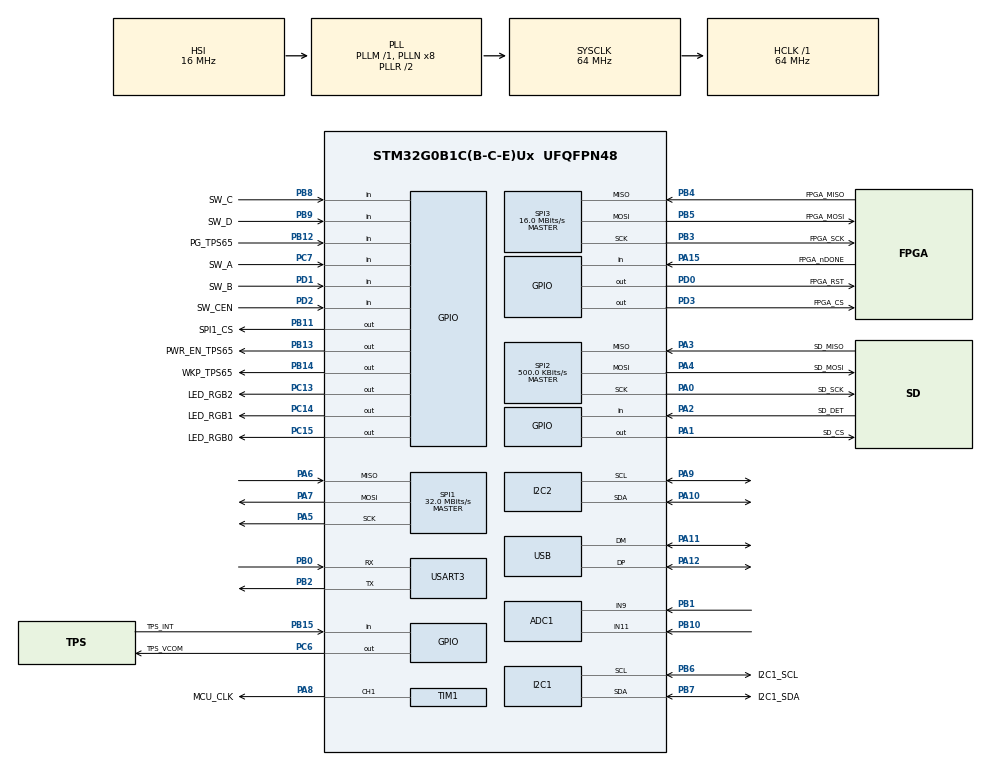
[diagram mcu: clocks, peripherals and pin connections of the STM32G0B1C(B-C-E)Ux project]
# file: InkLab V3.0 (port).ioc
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ADC1.Channel-0\#ChannelRegularConversion=ADC_CHANNEL_9
ADC1.NbrOfConversionFlag=1
ADC1.Rank-0\#ChannelRegularConversion=1
ADC1.SamplingTime-0\#ChannelRegularConversion=ADC_SAMPLINGTIME_COMMON_1
ADC1.SelectedChannel=ADC_CHANNEL_9|ADC_CHANNEL_11
ADC1.master=1
DAC1.DAC_Channel-DAC_OUT2_Int=DAC_CHANNEL_2
Dma.I2C1_RX.4.Direction=DMA_PERIPH_TO_MEMORY
Dma.I2C1_RX.4.EventEnable=DISABLE
Dma.I2C1_RX.4.Instance=DMA1_Channel5
Dma.I2C1_RX.4.MemDataAlignment=DMA_MDATAALIGN_BYTE
Dma.I2C1_RX.4.MemInc=DMA_MINC_ENABLE
Dma.I2C1_RX.4.Mode=DMA_NORMAL
Dma.I2C1_RX.4.PeriphDataAlignment=DMA_PDATAALIGN_BYTE
Dma.I2C1_RX.4.PeriphInc=DMA_PINC_DISABLE
Dma.I2C1_RX.4.Polarity=HAL_DMAMUX_REQ_GEN_RISING
Dma.I2C1_RX.4.Priority=DMA_PRIORITY_LOW
Dma.I2C1_RX.4.RequestNumber=1
Dma.I2C1_RX.4.SignalID=NONE
Dma.I2C1_RX.4.SyncEnable=DISABLE
Dma.I2C1_RX.4.SyncPolarity=HAL_DMAMUX_SYNC_NO_EVENT
Dma.I2C1_RX.4.SyncRequestNumber=1
Dma.I2C1_RX.4.SyncSignalID=NONE
Dma.I2C1_TX.5.Direction=DMA_MEMORY_TO_PERIPH
Dma.I2C1_TX.5.EventEnable=DISABLE
Dma.I2C1_TX.5.Instance=DMA1_Channel6
Dma.I2C1_TX.5.MemDataAlignment=DMA_MDATAALIGN_BYTE
Dma.I2C1_TX.5.MemInc=DMA_MINC_ENABLE
Dma.I2C1_TX.5.Mode=DMA_NORMAL
Dma.I2C1_TX.5.PeriphDataAlignment=DMA_PDATAALIGN_BYTE
Dma.I2C1_TX.5.PeriphInc=DMA_PINC_DISABLE
Dma.I2C1_TX.5.Polarity=HAL_DMAMUX_REQ_GEN_RISING
Dma.I2C1_TX.5.Priority=DMA_PRIORITY_LOW
Dma.I2C1_TX.5.RequestNumber=1
Dma.I2C1_TX.5.SignalID=NONE
Dma.I2C1_TX.5.SyncEnable=DISABLE
Dma.I2C1_TX.5.SyncPolarity=HAL_DMAMUX_SYNC_NO_EVENT
Dma.I2C1_TX.5.SyncRequestNumber=1
Dma.I2C1_TX.5.SyncSignalID=NONE
Dma.Request0=SPI2_RX
Dma.Request1=SPI2_TX
Dma.Request2=SPI3_RX
Dma.Request3=SPI3_TX
Dma.Request4=I2C1_RX
Dma.Request5=I2C1_TX
Dma.SPI2_RX.0.Direction=DMA_PERIPH_TO_MEMORY
Dma.SPI2_RX.0.EventEnable=DISABLE
Dma.SPI2_RX.0.Instance=DMA1_Channel1
Dma.SPI2_RX.0.MemDataAlignment=DMA_MDATAALIGN_BYTE
Dma.SPI2_RX.0.MemInc=DMA_MINC_ENABLE
Dma.SPI2_RX.0.Mode=DMA_NORMAL
Dma.SPI2_RX.0.PeriphDataAlignment=DMA_PDATAALIGN_BYTE
Dma.SPI2_RX.0.PeriphInc=DMA_PINC_DISABLE
Dma.SPI2_RX.0.Polarity=HAL_DMAMUX_REQ_GEN_RISING
Dma.SPI2_RX.0.Priority=DMA_PRIORITY_HIGH
Dma.SPI2_RX.0.RequestNumber=1
Dma.SPI2_RX.0.SignalID=NONE
Dma.SPI2_RX.0.SyncEnable=DISABLE
Dma.SPI2_RX.0.SyncPolarity=HAL_DMAMUX_SYNC_NO_EVENT
Dma.SPI2_RX.0.SyncRequestNumber=1
Dma.SPI2_RX.0.SyncSignalID=NONE
Dma.SPI2_TX.1.Direction=DMA_MEMORY_TO_PERIPH
Dma.SPI2_TX.1.EventEnable=DISABLE
Dma.SPI2_TX.1.Instance=DMA1_Channel2
Dma.SPI2_TX.1.MemDataAlignment=DMA_MDATAALIGN_BYTE
Dma.SPI2_TX.1.MemInc=DMA_MINC_ENABLE
Dma.SPI2_TX.1.Mode=DMA_NORMAL
Dma.SPI2_TX.1.PeriphDataAlignment=DMA_PDATAALIGN_BYTE
Dma.SPI2_TX.1.PeriphInc=DMA_PINC_DISABLE
Dma.SPI2_TX.1.Polarity=HAL_DMAMUX_REQ_GEN_RISING
Dma.SPI2_TX.1.Priority=DMA_PRIORITY_HIGH
Dma.SPI2_TX.1.RequestNumber=1
Dma.SPI2_TX.1.SignalID=NONE
Dma.SPI2_TX.1.SyncEnable=DISABLE
Dma.SPI2_TX.1.SyncPolarity=HAL_DMAMUX_SYNC_NO_EVENT
Dma.SPI2_TX.1.SyncRequestNumber=1
Dma.SPI2_TX.1.SyncSignalID=NONE
Dma.SPI3_RX.2.Direction=DMA_PERIPH_TO_MEMORY
Dma.SPI3_RX.2.EventEnable=DISABLE
Dma.SPI3_RX.2.Instance=DMA1_Channel3
Dma.SPI3_RX.2.MemDataAlignment=DMA_MDATAALIGN_BYTE
Dma.SPI3_RX.2.MemInc=DMA_MINC_ENABLE
Dma.SPI3_RX.2.Mode=DMA_NORMAL
Dma.SPI3_RX.2.PeriphDataAlignment=DMA_PDATAALIGN_BYTE
Dma.SPI3_RX.2.PeriphInc=DMA_PINC_DISABLE
Dma.SPI3_RX.2.Polarity=HAL_DMAMUX_REQ_GEN_RISING
Dma.SPI3_RX.2.Priority=DMA_PRIORITY_VERY_HIGH
Dma.SPI3_RX.2.RequestNumber=1
Dma.SPI3_RX.2.SignalID=NONE
Dma.SPI3_RX.2.SyncEnable=DISABLE
Dma.SPI3_RX.2.SyncPolarity=HAL_DMAMUX_SYNC_NO_EVENT
Dma.SPI3_RX.2.SyncRequestNumber=1
Dma.SPI3_RX.2.SyncSignalID=NONE
Dma.SPI3_TX.3.Direction=DMA_MEMORY_TO_PERIPH
Dma.SPI3_TX.3.EventEnable=DISABLE
Dma.SPI3_TX.3.Instance=DMA1_Channel4
Dma.SPI3_TX.3.MemDataAlignment=DMA_MDATAALIGN_BYTE
Dma.SPI3_TX.3.MemInc=DMA_MINC_ENABLE
Dma.SPI3_TX.3.Mode=DMA_NORMAL
Dma.SPI3_TX.3.PeriphDataAlignment=DMA_PDATAALIGN_BYTE
Dma.SPI3_TX.3.PeriphInc=DMA_PINC_DISABLE
Dma.SPI3_TX.3.Polarity=HAL_DMAMUX_REQ_GEN_RISING
Dma.SPI3_TX.3.Priority=DMA_PRIORITY_VERY_HIGH
Dma.SPI3_TX.3.RequestNumber=1
Dma.SPI3_TX.3.SignalID=NONE
Dma.SPI3_TX.3.SyncEnable=DISABLE
Dma.SPI3_TX.3.SyncPolarity=HAL_DMAMUX_SYNC_NO_EVENT
Dma.SPI3_TX.3.SyncRequestNumber=1
Dma.SPI3_TX.3.SyncSignalID=NONE
FATFS._FS_EXFAT=1
FATFS._USE_LFN=3
FREERTOS.Tasks01=defaultTask,24,128,StartDefaultTask,Default,NULL,Dynamic,NULL,NULL
FREERTOS.configCHECK_FOR_STACK_OVERFLOW=2
FREERTOS.configTOTAL_HEAP_SIZE=40960
FREERTOS.configUSE_NEWLIB_REENTRANT=1
FREERTOS.configUSE_TICKLESS_IDLE=0
I2C1.Timing=0x10B17DB5
I2C2.Timing=0x10B17DB5
Mcu.Family=STM32G0
Mcu.Name=STM32G0B1C(B-C-E)Ux
Mcu.Package=UFQFPN48
NVIC.DMA1_Ch4_7_DMA2_Ch1_5_DMAMUX1_OVR_IRQn=true\:3\:0\:false\:false\:true\:true\:false\:true\:true
NVIC.DMA1_Channel1_IRQn=true\:3\:0\:false\:false\:true\:true\:false\:true\:true
NVIC.DMA1_Channel2_3_IRQn=true\:3\:0\:false\:false\:true\:true\:false\:true\:true
NVIC.I2C1_IRQn=true\:3\:0\:false\:false\:true\:true\:true\:true\:true
NVIC.SPI2_3_IRQn=true\:3\:0\:false\:false\:true\:true\:true\:true\:true
NVIC.TIM6_DAC_LPTIM1_IRQn=true\:3\:0\:false\:false\:true\:true\:true\:true\:true
NVIC.TIM7_LPTIM2_IRQn=true\:3\:0\:false\:false\:true\:false\:false\:true\:true
NVIC.TimeBase=TIM7_LPTIM2_IRQn
NVIC.TimeBaseIP=TIM7
NVIC.USB_UCPD1_2_IRQn=true\:3\:0\:false\:false\:true\:true\:true\:true\:true
PA0.GPIO_Label=SD_SCK
PA0.Mode=Full_Duplex_Master
PA0.Signal=SPI2_SCK
PA1.GPIO_Label=SD_CS
PA1.Signal=GPIO_Output
PA10.Mode=I2C
PA10.Signal=I2C2_SDA
PA11\ [PA9].Mode=Device
PA11\ [PA9].Signal=USB_DM
PA12\ [PA10].Mode=Device
PA12\ [PA10].Signal=USB_DP
PA13.Mode=Serial_Wire
PA13.Signal=SYS_SWDIO
PA14-BOOT0.Mode=Serial_Wire
PA14-BOOT0.Signal=SYS_SWCLK
PA15.GPIO_Label=FPGA_nDONE
PA15.Signal=GPIO_Input
PA2.GPIO_Label=SD_DET
PA2.Signal=GPIO_Input
PA3.GPIO_Label=SD_MISO
PA3.Mode=Full_Duplex_Master
PA3.Signal=SPI2_MISO
PA4.GPIO_Label=SD_MOSI
PA4.Mode=Full_Duplex_Master
PA4.Signal=SPI2_MOSI
PA5.Mode=Full_Duplex_Master
PA5.Signal=SPI1_SCK
PA5.Stacked=true
PA6.Mode=Full_Duplex_Master
PA6.Signal=SPI1_MISO
PA7.Mode=Full_Duplex_Master
PA7.Signal=SPI1_MOSI
PA8.GPIO_Label=MCU_CLK
PA8.GPIO_Speed=GPIO_SPEED_FREQ_VERY_HIGH
PA8.Signal=S_TIM1_CH1
PA9.Mode=I2C
PA9.Signal=I2C2_SCL
PB0.Mode=Asynchronous
PB0.Signal=USART3_RX
PB1.Mode=IN9
PB1.Signal=ADC1_IN9
PB10.Mode=IN11
PB10.Signal=ADC1_IN11
PB11.GPIO_Label=SPI1_CS
PB11.Signal=GPIO_Output
PB12.GPIO_Label=PG_TPS65
PB12.Signal=GPIO_Input
PB13.GPIO_Label=PWR_EN_TPS65
PB13.Signal=GPIO_Output
PB14.GPIO_Label=WKP_TPS65
PB14.Signal=GPIO_Output
PB15.GPIO_Label=TPS_INT
PB15.Signal=GPIO_Input
PB2.Mode=Asynchronous
PB2.Signal=USART3_TX
PB3.GPIO_Label=FPGA_SCK
PB3.Mode=Full_Duplex_Master
PB3.Signal=SPI3_SCK
PB4.GPIO_Label=FPGA_MISO
PB4.Mode=Full_Duplex_Master
PB4.Signal=SPI3_MISO
PB5.GPIO_Label=FPGA_MOSI
PB5.Mode=Full_Duplex_Master
PB5.Signal=SPI3_MOSI
PB6.GPIO_Label=I2C1_SCL
PB6.Mode=I2C
PB6.Signal=I2C1_SCL
PB7.GPIO_Label=I2C1_SDA
PB7.Mode=I2C
PB7.Signal=I2C1_SDA
PB8.GPIO_Label=SW_C
PB8.GPIO_PuPd=GPIO_PULLUP
PB8.Signal=GPIO_Input
PB9.GPIO_Label=SW_D
PB9.GPIO_PuPd=GPIO_PULLUP
PB9.Signal=GPIO_Input
PC13.GPIO_Label=LED_RGB2
PC13.Signal=GPIO_Output
PC14-OSC32_IN\ (PC14).GPIO_Label=LED_RGB1
PC14-OSC32_IN\ (PC14).Signal=GPIO_Output
PC15-OSC32_OUT\ (PC15).GPIO_Label=LED_RGB0
PC15-OSC32_OUT\ (PC15).Signal=GPIO_Output
PC6.GPIO_Label=TPS_VCOM
PC6.Signal=GPIO_Output
PC7.GPIO_Label=SW_A
PC7.GPIO_PuPd=GPIO_PULLUP
PC7.Signal=GPIO_Input
PD0.GPIO_Label=FPGA_RST
PD0.Signal=GPIO_Output
PD1.GPIO_Label=SW_B
PD1.GPIO_PuPd=GPIO_PULLUP
PD1.Signal=GPIO_Input
PD2.GPIO_Label=SW_CEN
PD2.GPIO_PuPd=GPIO_PULLUP
PD2.Signal=GPIO_Input
PD3.GPIO_Label=FPGA_CS
PD3.Signal=GPIO_Output
ProjectManager.HeapSize=0x1000
ProjectManager.StackSize=0x1000
ProjectManager.TargetToolchain=STM32CubeIDE
RCC.ADCFreq_Value=64000000
RCC.AHBFreq_Value=64000000
RCC.CortexFreq_Value=64000000
RCC.EXTERNAL_CLOCK_VALUE=48000
RCC.HCLKFreq_Value=64000000
RCC.HSE_Timout=500
RCC.HSE_VALUE=12000000
RCC.HSI48_VALUE=48000000
RCC.HSI_VALUE=16000000
RCC.LSE_VALUE=32768
RCC.SYSCLKFreq_VALUE=64000000
RCC.SYSCLKSource=RCC_SYSCLKSOURCE_PLLCLK
RCC.USBFreq_Value=48000000
RCC.VCOOutputFreq_Value=128000000
SH.S_TIM1_CH1.0=TIM1_CH1,PWM Generation1 CH1
SPI1.BaudRatePrescaler=SPI_BAUDRATEPRESCALER_2
SPI1.CalculateBaudRate=32.0 MBits/s
SPI1.Direction=SPI_DIRECTION_2LINES
SPI1.Mode=SPI_MODE_MASTER
SPI1.VirtualType=VM_MASTER
SPI2.BaudRatePrescaler=SPI_BAUDRATEPRESCALER_128
SPI2.CalculateBaudRate=500.0 KBits/s
SPI2.DataSize=SPI_DATASIZE_8BIT
SPI2.Direction=SPI_DIRECTION_2LINES
SPI2.Mode=SPI_MODE_MASTER
SPI2.VirtualType=VM_MASTER
SPI3.BaudRatePrescaler=SPI_BAUDRATEPRESCALER_4
SPI3.CLKPhase=SPI_PHASE_2EDGE
SPI3.CLKPolarity=SPI_POLARITY_HIGH
SPI3.CalculateBaudRate=16.0 MBits/s
SPI3.DataSize=SPI_DATASIZE_8BIT
SPI3.Direction=SPI_DIRECTION_2LINES
SPI3.Mode=SPI_MODE_MASTER
SPI3.VirtualType=VM_MASTER
TIM1.Channel-Input_Capture2_from_TI2_Remap_TIM1=TIM_CHANNEL_2
TIM1.Channel-PWM\ Generation1\ CH1=TIM_CHANNEL_1
TIM6.AutoReloadPreload=TIM_AUTORELOAD_PRELOAD_ENABLE
TIM6.Period=40-1
TIM6.Prescaler=64-1
USART3.VirtualMode-Asynchronous=VM_ASYNC
USB_DEVICE.CLASS_NAME_FS=CDC
USB_DEVICE.PRODUCT_STRING_CDC_FS=Ink Lab V1.6
USB_DEVICE.VirtualMode=Cdc
USB_DEVICE.VirtualModeFS=Cdc_FS
USB_DRD_FS.low_power_enable=DISABLE
USB_DRD_FS.lpm_enable=DISABLE
VP_DAC1_VS_DACI2.Mode=DAC_OUT2_Int
VP_FATFS_VS_Generic.Mode=User_defined
VP_FREERTOS_VS_CMSIS_V2.Mode=CMSIS_V2
VP_RCC_USB.Mode=CRS SYNC Source USB
VP_SYS_VS_DBSignals.Mode=DisableDeadBatterySignals
VP_SYS_VS_tim7.Mode=TIM7
VP_TIM1_VS_NoInput2.Mode=Input_Capture2_from_TI2_Remap_TIM1
VP_TIM6_VS_ClockSourceINT.Mode=Enable_Timer
VP_USB_DEVICE_VS_USB_DEVICE_CDC_FS.Mode=CDC_FS
board=custom

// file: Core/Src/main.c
/* USER CODE BEGIN Header */
/**
  ******************************************************************************
  * @file           : main.c
  * @brief          : Main program body
  ******************************************************************************
  */
/* USER CODE END Header */
#include "main.h"
#include "cmsis_os.h"
#include "app_fatfs.h"
#include "usb_device.h"

/* USER CODE BEGIN Includes */
#include "bq25798.h"
#include "led_manager.h"
/* USER CODE END Includes */

ADC_HandleTypeDef hadc1;

DAC_HandleTypeDef hdac1;

I2C_HandleTypeDef hi2c1;
I2C_HandleTypeDef hi2c2;
DMA_HandleTypeDef hdma_i2c1_rx;
DMA_HandleTypeDef hdma_i2c1_tx;

SPI_HandleTypeDef hspi1;
SPI_HandleTypeDef hspi2;
SPI_HandleTypeDef hspi3;
DMA_HandleTypeDef hdma_spi2_rx;
DMA_HandleTypeDef hdma_spi2_tx;
DMA_HandleTypeDef hdma_spi3_rx;
DMA_HandleTypeDef hdma_spi3_tx;

TIM_HandleTypeDef htim1;
TIM_HandleTypeDef htim6;

UART_HandleTypeDef huart3;

/* Definitions for defaultTask */
osThreadId_t defaultTaskHandle;
const osThreadAttr_t defaultTask_attributes = {
  .name = "defaultTask",
  .priority = (osPriority_t) osPriorityNormal,
  .stack_size = 128 * 4
};

void SystemClock_Config(void);
static void MX_GPIO_Init(void);
static void MX_DMA_Init(void);
static void MX_SPI2_Init(void);
static void MX_SPI3_Init(void);
static void MX_TIM1_Init(void);
static void MX_I2C1_Init(void);
static void MX_I2C2_Init(void);
static void MX_SPI1_Init(void);
static void MX_ADC1_Init(void);
static void MX_USART3_UART_Init(void);
static void MX_TIM6_Init(void);
static void MX_DAC1_Init(void);
void StartDefaultTask(void *argument);

/* USER CODE BEGIN PFP */
// Tell main.c that this function exists inside app_freertos.c!
extern void Init_App_RTOS(void);
/* USER CODE END PFP */

int main(void)
{

  /* MCU Configuration--------------------------------------------------------*/

  /* Reset of all peripherals, Initializes the Flash interface and the Systick. */
  HAL_Init();

  /* Configure the system clock */
  SystemClock_Config();

  /* USER CODE BEGIN SysInit */
	  __HAL_RCC_PWR_CLK_ENABLE();
	  __HAL_RCC_RTCAPB_CLK_ENABLE();
	  HAL_PWR_EnableBkUpAccess();

	  // CHECK FOR FAILED OTA UPDATE
	  if (TAMP->BKP0R == 0x4F544150) {

		  // NEW LOGIC: Only roll back if the reset was NOT an Option Byte Launch.
		  // If it was an OBLRST, this is a normal OTA reboot, so we leave the flag alone!
		  if (!__HAL_RCC_GET_FLAG(RCC_FLAG_OBLRST)) {

			  TAMP->BKP0R = 0; // Clear the flag to prevent infinite loops

			  HAL_FLASH_Unlock();
			  HAL_FLASH_OB_Unlock();

			  // Swap the banks back to the original working firmware!
			  if (READ_BIT(FLASH->OPTR, FLASH_OPTR_nSWAP_BANK)) {
				  CLEAR_BIT(FLASH->OPTR, FLASH_OPTR_nSWAP_BANK);
			  } else {
				  SET_BIT(FLASH->OPTR, FLASH_OPTR_nSWAP_BANK);
			  }

			  SET_BIT(FLASH->CR, FLASH_CR_OPTSTRT);
			  while (__HAL_FLASH_GET_FLAG(FLASH_FLAG_BSY)) {}
			  HAL_FLASH_OB_Launch(); // Reboot back to safety
		  }
	  }

	  __HAL_RCC_CLEAR_RESET_FLAGS();
  /* USER CODE END SysInit */

  /* Initialize all configured peripherals */
  MX_GPIO_Init();
  MX_DMA_Init();
  MX_SPI2_Init();
  MX_SPI3_Init();
  MX_TIM1_Init();
  MX_I2C1_Init();
  MX_I2C2_Init();
  if (MX_FATFS_Init() != APP_OK) {
    Error_Handler();
  }
  MX_SPI1_Init();
  MX_ADC1_Init();
  MX_USART3_UART_Init();
  MX_TIM6_Init();
  MX_DAC1_Init();
  /* USER CODE BEGIN 2 */
  HAL_TIM_Base_Start_IT(&htim6);
  /* USER CODE END 2 */

  /* Init scheduler */
  osKernelInitialize();

  /* Create the thread(s) */
  /* creation of defaultTask */
  defaultTaskHandle = osThreadNew(StartDefaultTask, NULL, &defaultTask_attributes);

  /* USER CODE BEGIN RTOS_THREADS */

  // Call the function we made in app_freertos.c to create all our custom queues and tasks cleanly!
  Init_App_RTOS();

  /* USER CODE END RTOS_THREADS */

  /* Start scheduler */
  osKernelStart();

  /* We should never get here as control is now taken by the scheduler */

  /* Infinite loop */
  while (1)
  {

  }
}

void SystemClock_Config(void)
{
  RCC_OscInitTypeDef RCC_OscInitStruct = {0};
  RCC_ClkInitTypeDef RCC_ClkInitStruct = {0};
  RCC_CRSInitTypeDef pInit = {0};

  /** Configure the main internal regulator output voltage
  */
  HAL_PWREx_ControlVoltageScaling(PWR_REGULATOR_VOLTAGE_SCALE1);

  /** Initializes the RCC Oscillators according to the specified parameters
  * in the RCC_OscInitTypeDef structure.
  */
  RCC_OscInitStruct.OscillatorType = RCC_OSCILLATORTYPE_HSI|RCC_OSCILLATORTYPE_HSI48;
  RCC_OscInitStruct.HSIState = RCC_HSI_ON;
  RCC_OscInitStruct.HSI48State = RCC_HSI48_ON;
  RCC_OscInitStruct.HSIDiv = RCC_HSI_DIV1;
  RCC_OscInitStruct.HSICalibrationValue = RCC_HSICALIBRATION_DEFAULT;
  RCC_OscInitStruct.PLL.PLLState = RCC_PLL_ON;
  RCC_OscInitStruct.PLL.PLLSource = RCC_PLLSOURCE_HSI;
  RCC_OscInitStruct.PLL.PLLM = RCC_PLLM_DIV1;
  RCC_OscInitStruct.PLL.PLLN = 8;
  RCC_OscInitStruct.PLL.PLLP = RCC_PLLP_DIV2;
  RCC_OscInitStruct.PLL.PLLQ = RCC_PLLQ_DIV2;
  RCC_OscInitStruct.PLL.PLLR = RCC_PLLR_DIV2;
  if (HAL_RCC_OscConfig(&RCC_OscInitStruct) != HAL_OK)
  {
    Error_Handler();
  }

  /** Initializes the CPU, AHB and APB buses clocks
  */
  RCC_ClkInitStruct.ClockType = RCC_CLOCKTYPE_HCLK|RCC_CLOCKTYPE_SYSCLK
                              |RCC_CLOCKTYPE_PCLK1;
  RCC_ClkInitStruct.SYSCLKSource = RCC_SYSCLKSOURCE_PLLCLK;
  RCC_ClkInitStruct.AHBCLKDivider = RCC_SYSCLK_DIV1;
  RCC_ClkInitStruct.APB1CLKDivider = RCC_HCLK_DIV1;

  if (HAL_RCC_ClockConfig(&RCC_ClkInitStruct, FLASH_LATENCY_2) != HAL_OK)
  {
    Error_Handler();
  }

  /** Enable the SYSCFG APB clock
  */
  __HAL_RCC_CRS_CLK_ENABLE();

  /** Configures CRS
  */
  pInit.Prescaler = RCC_CRS_SYNC_DIV1;
  pInit.Source = RCC_CRS_SYNC_SOURCE_USB;
  pInit.Polarity = RCC_CRS_SYNC_POLARITY_RISING;
  pInit.ReloadValue = __HAL_RCC_CRS_RELOADVALUE_CALCULATE(48000000,1000);
  pInit.ErrorLimitValue = 34;
  pInit.HSI48CalibrationValue = 32;

  HAL_RCCEx_CRSConfig(&pInit);
}

static void MX_ADC1_Init(void)
{

  ADC_ChannelConfTypeDef sConfig = {0};

  /** Configure the global features of the ADC (Clock, Resolution, Data Alignment and number of conversion)
  */
  hadc1.Instance = ADC1;
  hadc1.Init.ClockPrescaler = ADC_CLOCK_SYNC_PCLK_DIV2;
  hadc1.Init.Resolution = ADC_RESOLUTION_12B;
  hadc1.Init.DataAlign = ADC_DATAALIGN_RIGHT;
  hadc1.Init.ScanConvMode = ADC_SCAN_DISABLE;
  hadc1.Init.EOCSelection = ADC_EOC_SINGLE_CONV;
  hadc1.Init.LowPowerAutoWait = DISABLE;
  hadc1.Init.LowPowerAutoPowerOff = DISABLE;
  hadc1.Init.ContinuousConvMode = DISABLE;
  hadc1.Init.NbrOfConversion = 1;
  hadc1.Init.DiscontinuousConvMode = DISABLE;
  hadc1.Init.ExternalTrigConv = ADC_SOFTWARE_START;
  hadc1.Init.ExternalTrigConvEdge = ADC_EXTERNALTRIGCONVEDGE_NONE;
  hadc1.Init.DMAContinuousRequests = DISABLE;
  hadc1.Init.Overrun = ADC_OVR_DATA_PRESERVED;
  hadc1.Init.SamplingTimeCommon1 = ADC_SAMPLETIME_1CYCLE_5;
  hadc1.Init.SamplingTimeCommon2 = ADC_SAMPLETIME_1CYCLE_5;
  hadc1.Init.OversamplingMode = DISABLE;
  hadc1.Init.TriggerFrequencyMode = ADC_TRIGGER_FREQ_HIGH;
  if (HAL_ADC_Init(&hadc1) != HAL_OK)
  {
    Error_Handler();
  }

  /** Configure Regular Channel
  */
  sConfig.Channel = ADC_CHANNEL_9;
  sConfig.Rank = ADC_REGULAR_RANK_1;
  sConfig.SamplingTime = ADC_SAMPLINGTIME_COMMON_1;
  if (HAL_ADC_ConfigChannel(&hadc1, &sConfig) != HAL_OK)
  {
    Error_Handler();
  }

}

static void MX_DAC1_Init(void)
{

  DAC_ChannelConfTypeDef sConfig = {0};

  /** DAC Initialization
  */
  hdac1.Instance = DAC1;
  if (HAL_DAC_Init(&hdac1) != HAL_OK)
  {
    Error_Handler();
  }

  /** DAC channel OUT2 config
  */
  sConfig.DAC_SampleAndHold = DAC_SAMPLEANDHOLD_DISABLE;
  sConfig.DAC_Trigger = DAC_TRIGGER_NONE;
  sConfig.DAC_OutputBuffer = DAC_OUTPUTBUFFER_DISABLE;
  sConfig.DAC_ConnectOnChipPeripheral = DAC_CHIPCONNECT_ENABLE;
  sConfig.DAC_UserTrimming = DAC_TRIMMING_FACTORY;
  if (HAL_DAC_ConfigChannel(&hdac1, &sConfig, DAC_CHANNEL_2) != HAL_OK)
  {
    Error_Handler();
  }

}

static void MX_I2C1_Init(void)
{

  hi2c1.Instance = I2C1;
  hi2c1.Init.Timing = 0x10B17DB5;
  hi2c1.Init.OwnAddress1 = 0;
  hi2c1.Init.AddressingMode = I2C_ADDRESSINGMODE_7BIT;
  hi2c1.Init.DualAddressMode = I2C_DUALADDRESS_DISABLE;
  hi2c1.Init.OwnAddress2 = 0;
  hi2c1.Init.OwnAddress2Masks = I2C_OA2_NOMASK;
  hi2c1.Init.GeneralCallMode = I2C_GENERALCALL_DISABLE;
  hi2c1.Init.NoStretchMode = I2C_NOSTRETCH_DISABLE;
  if (HAL_I2C_Init(&hi2c1) != HAL_OK)
  {
    Error_Handler();
  }

  /** Configure Analogue filter
  */
  if (HAL_I2CEx_ConfigAnalogFilter(&hi2c1, I2C_ANALOGFILTER_ENABLE) != HAL_OK)
  {
    Error_Handler();
  }

  /** Configure Digital filter
  */
  if (HAL_I2CEx_ConfigDigitalFilter(&hi2c1, 0) != HAL_OK)
  {
    Error_Handler();
  }

}

static void MX_I2C2_Init(void)
{

  hi2c2.Instance = I2C2;
  hi2c2.Init.Timing = 0x10B17DB5;
  hi2c2.Init.OwnAddress1 = 0;
  hi2c2.Init.AddressingMode = I2C_ADDRESSINGMODE_7BIT;
  hi2c2.Init.DualAddressMode = I2C_DUALADDRESS_DISABLE;
  hi2c2.Init.OwnAddress2 = 0;
  hi2c2.Init.OwnAddress2Masks = I2C_OA2_NOMASK;
  hi2c2.Init.GeneralCallMode = I2C_GENERALCALL_DISABLE;
  hi2c2.Init.NoStretchMode = I2C_NOSTRETCH_DISABLE;
  if (HAL_I2C_Init(&hi2c2) != HAL_OK)
  {
    Error_Handler();
  }

  /** Configure Analogue filter
  */
  if (HAL_I2CEx_ConfigAnalogFilter(&hi2c2, I2C_ANALOGFILTER_ENABLE) != HAL_OK)
  {
    Error_Handler();
  }

  /** Configure Digital filter
  */
  if (HAL_I2CEx_ConfigDigitalFilter(&hi2c2, 0) != HAL_OK)
  {
    Error_Handler();
  }

}

static void MX_SPI1_Init(void)
{

  /* SPI1 parameter configuration*/
  hspi1.Instance = SPI1;
  hspi1.Init.Mode = SPI_MODE_MASTER;
  hspi1.Init.Direction = SPI_DIRECTION_2LINES;
  hspi1.Init.DataSize = SPI_DATASIZE_4BIT;
  hspi1.Init.CLKPolarity = SPI_POLARITY_LOW;
  hspi1.Init.CLKPhase = SPI_PHASE_1EDGE;
  hspi1.Init.NSS = SPI_NSS_SOFT;
  hspi1.Init.BaudRatePrescaler = SPI_BAUDRATEPRESCALER_2;
  hspi1.Init.FirstBit = SPI_FIRSTBIT_MSB;
  hspi1.Init.TIMode = SPI_TIMODE_DISABLE;
  hspi1.Init.CRCCalculation = SPI_CRCCALCULATION_DISABLE;
  hspi1.Init.CRCPolynomial = 7;
  hspi1.Init.CRCLength = SPI_CRC_LENGTH_DATASIZE;
  hspi1.Init.NSSPMode = SPI_NSS_PULSE_ENABLE;
  if (HAL_SPI_Init(&hspi1) != HAL_OK)
  {
    Error_Handler();
  }

}

static void MX_SPI2_Init(void)
{

  /* SPI2 parameter configuration*/
  hspi2.Instance = SPI2;
  hspi2.Init.Mode = SPI_MODE_MASTER;
  hspi2.Init.Direction = SPI_DIRECTION_2LINES;
  hspi2.Init.DataSize = SPI_DATASIZE_8BIT;
  hspi2.Init.CLKPolarity = SPI_POLARITY_LOW;
  hspi2.Init.CLKPhase = SPI_PHASE_1EDGE;
  hspi2.Init.NSS = SPI_NSS_SOFT;
  hspi2.Init.BaudRatePrescaler = SPI_BAUDRATEPRESCALER_128;
  hspi2.Init.FirstBit = SPI_FIRSTBIT_MSB;
  hspi2.Init.TIMode = SPI_TIMODE_DISABLE;
  hspi2.Init.CRCCalculation = SPI_CRCCALCULATION_DISABLE;
  hspi2.Init.CRCPolynomial = 7;
  hspi2.Init.CRCLength = SPI_CRC_LENGTH_DATASIZE;
  hspi2.Init.NSSPMode = SPI_NSS_PULSE_ENABLE;
  if (HAL_SPI_Init(&hspi2) != HAL_OK)
  {
    Error_Handler();
  }

}

static void MX_SPI3_Init(void)
{

  /* SPI3 parameter configuration*/
  hspi3.Instance = SPI3;
  hspi3.Init.Mode = SPI_MODE_MASTER;
  hspi3.Init.Direction = SPI_DIRECTION_2LINES;
  hspi3.Init.DataSize = SPI_DATASIZE_8BIT;
  hspi3.Init.CLKPolarity = SPI_POLARITY_HIGH;
  hspi3.Init.CLKPhase = SPI_PHASE_2EDGE;
  hspi3.Init.NSS = SPI_NSS_SOFT;
  hspi3.Init.BaudRatePrescaler = SPI_BAUDRATEPRESCALER_4;
  hspi3.Init.FirstBit = SPI_FIRSTBIT_MSB;
  hspi3.Init.TIMode = SPI_TIMODE_DISABLE;
  hspi3.Init.CRCCalculation = SPI_CRCCALCULATION_DISABLE;
  hspi3.Init.CRCPolynomial = 7;
  hspi3.Init.CRCLength = SPI_CRC_LENGTH_DATASIZE;
  hspi3.Init.NSSPMode = SPI_NSS_PULSE_DISABLE;
  if (HAL_SPI_Init(&hspi3) != HAL_OK)
  {
    Error_Handler();
  }

}

static void MX_TIM1_Init(void)
{

  TIM_MasterConfigTypeDef sMasterConfig = {0};
  TIM_OC_InitTypeDef sConfigOC = {0};
  TIM_IC_InitTypeDef sConfigIC = {0};
  TIM_BreakDeadTimeConfigTypeDef sBreakDeadTimeConfig = {0};

  htim1.Instance = TIM1;
  htim1.Init.Prescaler = 0;
  htim1.Init.CounterMode = TIM_COUNTERMODE_UP;
  htim1.Init.Period = 65535;
  htim1.Init.ClockDivision = TIM_CLOCKDIVISION_DIV1;
  htim1.Init.RepetitionCounter = 0;
  htim1.Init.AutoReloadPreload = TIM_AUTORELOAD_PRELOAD_DISABLE;
  if (HAL_TIM_PWM_Init(&htim1) != HAL_OK)
  {
    Error_Handler();
  }
  if (HAL_TIM_IC_Init(&htim1) != HAL_OK)
  {
    Error_Handler();
  }
  sMasterConfig.MasterOutputTrigger = TIM_TRGO_RESET;
  sMasterConfig.MasterOutputTrigger2 = TIM_TRGO2_RESET;
  sMasterConfig.MasterSlaveMode = TIM_MASTERSLAVEMODE_DISABLE;
  if (HAL_TIMEx_MasterConfigSynchronization(&htim1, &sMasterConfig) != HAL_OK)
  {
    Error_Handler();
  }
  sConfigOC.OCMode = TIM_OCMODE_PWM1;
  sConfigOC.Pulse = 0;
  sConfigOC.OCPolarity = TIM_OCPOLARITY_HIGH;
  sConfigOC.OCNPolarity = TIM_OCNPOLARITY_HIGH;
  sConfigOC.OCFastMode = TIM_OCFAST_DISABLE;
  sConfigOC.OCIdleState = TIM_OCIDLESTATE_RESET;
  sConfigOC.OCNIdleState = TIM_OCNIDLESTATE_RESET;
  if (HAL_TIM_PWM_ConfigChannel(&htim1, &sConfigOC, TIM_CHANNEL_1) != HAL_OK)
  {
    Error_Handler();
  }
  sConfigIC.ICPolarity = TIM_INPUTCHANNELPOLARITY_RISING;
  sConfigIC.ICSelection = TIM_ICSELECTION_DIRECTTI;
  sConfigIC.ICPrescaler = TIM_ICPSC_DIV1;
  sConfigIC.ICFilter = 0;
  if (HAL_TIM_IC_ConfigChannel(&htim1, &sConfigIC, TIM_CHANNEL_2) != HAL_OK)
  {
    Error_Handler();
  }
  if (HAL_TIMEx_TISelection(&htim1, TIM_TIM1_TI2_COMP2, TIM_CHANNEL_2) != HAL_OK)
  {
    Error_Handler();
  }
  sBreakDeadTimeConfig.OffStateRunMode = TIM_OSSR_DISABLE;
  sBreakDeadTimeConfig.OffStateIDLEMode = TIM_OSSI_DISABLE;
  sBreakDeadTimeConfig.LockLevel = TIM_LOCKLEVEL_OFF;
  sBreakDeadTimeConfig.DeadTime = 0;
  sBreakDeadTimeConfig.BreakState = TIM_BREAK_DISABLE;
  sBreakDeadTimeConfig.BreakPolarity = TIM_BREAKPOLARITY_HIGH;
  sBreakDeadTimeConfig.BreakFilter = 0;
  sBreakDeadTimeConfig.BreakAFMode = TIM_BREAK_AFMODE_INPUT;
  sBreakDeadTimeConfig.Break2State = TIM_BREAK2_DISABLE;
  sBreakDeadTimeConfig.Break2Polarity = TIM_BREAK2POLARITY_HIGH;
  sBreakDeadTimeConfig.Break2Filter = 0;
  sBreakDeadTimeConfig.Break2AFMode = TIM_BREAK_AFMODE_INPUT;
  sBreakDeadTimeConfig.AutomaticOutput = TIM_AUTOMATICOUTPUT_DISABLE;
  if (HAL_TIMEx_ConfigBreakDeadTime(&htim1, &sBreakDeadTimeConfig) != HAL_OK)
  {
    Error_Handler();
  }
  HAL_TIM_MspPostInit(&htim1);

}

static void MX_TIM6_Init(void)
{

  TIM_MasterConfigTypeDef sMasterConfig = {0};

  htim6.Instance = TIM6;
  htim6.Init.Prescaler = 64-1;
  htim6.Init.CounterMode = TIM_COUNTERMODE_UP;
  htim6.Init.Period = 40-1;
  htim6.Init.AutoReloadPreload = TIM_AUTORELOAD_PRELOAD_ENABLE;
  if (HAL_TIM_Base_Init(&htim6) != HAL_OK)
  {
    Error_Handler();
  }
  sMasterConfig.MasterOutputTrigger = TIM_TRGO_RESET;
  sMasterConfig.MasterSlaveMode = TIM_MASTERSLAVEMODE_DISABLE;
  if (HAL_TIMEx_MasterConfigSynchronization(&htim6, &sMasterConfig) != HAL_OK)
  {
    Error_Handler();
  }

}

static void MX_USART3_UART_Init(void)
{

  huart3.Instance = USART3;
  huart3.Init.BaudRate = 115200;
  huart3.Init.WordLength = UART_WORDLENGTH_8B;
  huart3.Init.StopBits = UART_STOPBITS_1;
  huart3.Init.Parity = UART_PARITY_NONE;
  huart3.Init.Mode = UART_MODE_TX_RX;
  huart3.Init.HwFlowCtl = UART_HWCONTROL_NONE;
  huart3.Init.OverSampling = UART_OVERSAMPLING_16;
  huart3.Init.OneBitSampling = UART_ONE_BIT_SAMPLE_DISABLE;
  huart3.Init.ClockPrescaler = UART_PRESCALER_DIV1;
  huart3.AdvancedInit.AdvFeatureInit = UART_ADVFEATURE_NO_INIT;
  if (HAL_UART_Init(&huart3) != HAL_OK)
  {
    Error_Handler();
  }
  if (HAL_UARTEx_SetTxFifoThreshold(&huart3, UART_TXFIFO_THRESHOLD_1_8) != HAL_OK)
  {
    Error_Handler();
  }
  if (HAL_UARTEx_SetRxFifoThreshold(&huart3, UART_RXFIFO_THRESHOLD_1_8) != HAL_OK)
  {
    Error_Handler();
  }
  if (HAL_UARTEx_DisableFifoMode(&huart3) != HAL_OK)
  {
    Error_Handler();
  }

}

static void MX_DMA_Init(void)
{

  /* DMA controller clock enable */
  __HAL_RCC_DMA1_CLK_ENABLE();

  /* DMA interrupt init */
  /* DMA1_Channel1_IRQn interrupt configuration */
  HAL_NVIC_SetPriority(DMA1_Channel1_IRQn, 3, 0);
  HAL_NVIC_EnableIRQ(DMA1_Channel1_IRQn);
  /* DMA1_Channel2_3_IRQn interrupt configuration */
  HAL_NVIC_SetPriority(DMA1_Channel2_3_IRQn, 3, 0);
  HAL_NVIC_EnableIRQ(DMA1_Channel2_3_IRQn);
  /* DMA1_Ch4_7_DMA2_Ch1_5_DMAMUX1_OVR_IRQn interrupt configuration */
  HAL_NVIC_SetPriority(DMA1_Ch4_7_DMA2_Ch1_5_DMAMUX1_OVR_IRQn, 3, 0);
  HAL_NVIC_EnableIRQ(DMA1_Ch4_7_DMA2_Ch1_5_DMAMUX1_OVR_IRQn);

}

static void MX_GPIO_Init(void)
{
  GPIO_InitTypeDef GPIO_InitStruct = {0};

  /* GPIO Ports Clock Enable */
  __HAL_RCC_GPIOC_CLK_ENABLE();
  __HAL_RCC_GPIOA_CLK_ENABLE();
  __HAL_RCC_GPIOB_CLK_ENABLE();
  __HAL_RCC_GPIOD_CLK_ENABLE();

  /*Configure GPIO pin Output Level */
  HAL_GPIO_WritePin(GPIOC, LED_RGB2_Pin|LED_RGB1_Pin|LED_RGB0_Pin|GPIO_PIN_6, GPIO_PIN_RESET);

  /*Configure GPIO pin Output Level */
  HAL_GPIO_WritePin(SD_CS_GPIO_Port, SD_CS_Pin, GPIO_PIN_RESET);

  /*Configure GPIO pin Output Level */
  HAL_GPIO_WritePin(GPIOB, GPIO_PIN_11|PWR_EN_TPS65_Pin|WKP_TPS65_Pin, GPIO_PIN_RESET);

  /*Configure GPIO pin Output Level */
  HAL_GPIO_WritePin(GPIOD, FPGA_RST_Pin|FPGA_CS_Pin, GPIO_PIN_RESET);

  /*Configure GPIO pins : LED_RGB2_Pin LED_RGB1_Pin LED_RGB0_Pin PC6 */
  GPIO_InitStruct.Pin = LED_RGB2_Pin|LED_RGB1_Pin|LED_RGB0_Pin|GPIO_PIN_6;
  GPIO_InitStruct.Mode = GPIO_MODE_OUTPUT_PP;
  GPIO_InitStruct.Pull = GPIO_NOPULL;
  GPIO_InitStruct.Speed = GPIO_SPEED_FREQ_LOW;
  HAL_GPIO_Init(GPIOC, &GPIO_InitStruct);

  /*Configure GPIO pin : SD_CS_Pin */
  GPIO_InitStruct.Pin = SD_CS_Pin;
  GPIO_InitStruct.Mode = GPIO_MODE_OUTPUT_PP;
  GPIO_InitStruct.Pull = GPIO_NOPULL;
  GPIO_InitStruct.Speed = GPIO_SPEED_FREQ_LOW;
  HAL_GPIO_Init(SD_CS_GPIO_Port, &GPIO_InitStruct);

  /*Configure GPIO pins : SD_DET_Pin FPGA_nDONE_Pin */
  GPIO_InitStruct.Pin = SD_DET_Pin|FPGA_nDONE_Pin;
  GPIO_InitStruct.Mode = GPIO_MODE_INPUT;
  GPIO_InitStruct.Pull = GPIO_NOPULL;
  HAL_GPIO_Init(GPIOA, &GPIO_InitStruct);

  /*Configure GPIO pins : PB11 PWR_EN_TPS65_Pin WKP_TPS65_Pin */
  GPIO_InitStruct.Pin = GPIO_PIN_11|PWR_EN_TPS65_Pin|WKP_TPS65_Pin;
  GPIO_InitStruct.Mode = GPIO_MODE_OUTPUT_PP;
  GPIO_InitStruct.Pull = GPIO_NOPULL;
  GPIO_InitStruct.Speed = GPIO_SPEED_FREQ_LOW;
  HAL_GPIO_Init(GPIOB, &GPIO_InitStruct);

  /*Configure GPIO pins : PG_TPS65_Pin PB15 */
  GPIO_InitStruct.Pin = PG_TPS65_Pin|GPIO_PIN_15;
  GPIO_InitStruct.Mode = GPIO_MODE_INPUT;
  GPIO_InitStruct.Pull = GPIO_NOPULL;
  HAL_GPIO_Init(GPIOB, &GPIO_InitStruct);

  /*Configure GPIO pin : SW_A_Pin */
  GPIO_InitStruct.Pin = SW_A_Pin;
  GPIO_InitStruct.Mode = GPIO_MODE_INPUT;
  GPIO_InitStruct.Pull = GPIO_PULLUP;
  HAL_GPIO_Init(SW_A_GPIO_Port, &GPIO_InitStruct);

  /*Configure GPIO pins : FPGA_RST_Pin FPGA_CS_Pin */
  GPIO_InitStruct.Pin = FPGA_RST_Pin|FPGA_CS_Pin;
  GPIO_InitStruct.Mode = GPIO_MODE_OUTPUT_PP;
  GPIO_InitStruct.Pull = GPIO_NOPULL;
  GPIO_InitStruct.Speed = GPIO_SPEED_FREQ_LOW;
  HAL_GPIO_Init(GPIOD, &GPIO_InitStruct);

  /*Configure GPIO pins : SW_B_Pin SW_CEN_Pin */
  GPIO_InitStruct.Pin = SW_B_Pin|SW_CEN_Pin;
  GPIO_InitStruct.Mode = GPIO_MODE_INPUT;
  GPIO_InitStruct.Pull = GPIO_PULLUP;
  HAL_GPIO_Init(GPIOD, &GPIO_InitStruct);

  /*Configure GPIO pins : SW_C_Pin SW_D_Pin */
  GPIO_InitStruct.Pin = SW_C_Pin|SW_D_Pin;
  GPIO_InitStruct.Mode = GPIO_MODE_INPUT;
  GPIO_InitStruct.Pull = GPIO_PULLUP;
  HAL_GPIO_Init(GPIOB, &GPIO_InitStruct);

}

/* USER CODE BEGIN 4 */
void App_Resume_SPI(void) {
    // These static functions belong to main.c, so we can call them here
    MX_SPI2_Init();
    MX_SPI3_Init();
}

/* USER CODE END 4 */

void StartDefaultTask(void *argument)
{
  /* init code for USB_Device */
  MX_USB_Device_Init();
  for(;;)
  {
    osDelay(1);
  }
}

void HAL_TIM_PeriodElapsedCallback(TIM_HandleTypeDef *htim)
{
  if (htim->Instance == TIM7)
  {
    HAL_IncTick();
  }
  /* USER CODE BEGIN Callback 1 */

  // 25kHz Software PWM & Status Machine
  if (htim->Instance == TIM6) {
    LED_PWM_Tick();
  }
  /* USER CODE END Callback 1 */
}

void Error_Handler(void)
{
  __disable_irq();
  while (1)
  {
  }
}

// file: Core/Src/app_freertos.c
/* USER CODE BEGIN Header */
/**
  ******************************************************************************
  * @file           : app_freertos.c
  * @brief          : Cleaned and Decoupled RTOS Application Entry
  ******************************************************************************
  */
/* USER CODE END Header */

#include "FreeRTOS.h"
#include "task.h"
#include "main.h"

/* USER CODE BEGIN Includes */
#include <stdio.h>
#include <stdarg.h>
#include <string.h>

#include "usbd_cdc_if.h"
#include "app_fatfs.h"
#include "fpga.h"
#include "frontend_api.h"
#include "bq25798.h"
#include "powerMonitor.h"

// --- New Modular Libraries ---
#include "battery_soc.h"
#include "sys_power.h"
#include "led_manager.h"
#include "joystick.h"
#include "diagnostics.h"
#include "error_manager.h"
#include "pinmux.h"
#include "main.h"

/* USER CODE END Includes */

/* USER CODE BEGIN PTD */
#define USB_MSG_MAX_LEN 256
typedef struct {
    char data[USB_MSG_MAX_LEN];
} UsbMsg_t;

typedef enum {
    TARGET_NONE,
    TARGET_INA_1V2,
    TARGET_INA_3V3EXT,
    TARGET_INA_3V3FPGA,
    TARGET_INA_3V3MCU,
    TARGET_BQ_VBUS,
    TARGET_BQ_VBAT
} FastTarget_t;
/* USER CODE END PTD */

/* USER CODE BEGIN PD */
#define NUM_BITSTREAMS 16
#define RX_RING_SIZE   8192
#define MAX_NAME_LEN   16
/* USER CODE END PD */

/* USER CODE BEGIN Variables */
osMessageQueueId_t UsbQueueHandle;
osThreadId_t UsbTaskHandle;
osThreadId_t JoystickTaskHandle;
osThreadId_t LedTaskHandle;
osThreadId_t TelemetryTaskHandle;
osThreadId_t FpgaTaskHandle;
osMessageQueueId_t FpgaTxQueueHandle;
FpgaSpiPacket_t fpga_rx_packet;

extern USBD_HandleTypeDef hUsbDeviceFS;
extern I2C_HandleTypeDef hi2c1;
extern TIM_HandleTypeDef htim1;
PowerMonitor_t ina_1v2_core, ina_3v3_ext, ina_3v3_fpga, ina_3v3_stm32;
extern osSemaphoreId_t FpgaDmaSemaphore;
osSemaphoreId_t UsbRxSemaphore = NULL;
osSemaphoreId_t UsbTxSemaphore = NULL;
osSemaphoreId_t I2c1DmaSemaphore = NULL;
osMutexId_t I2c1Mutex = NULL;

volatile uint8_t rx_ring_buf[RX_RING_SIZE];
volatile uint16_t rx_ring_head = 0;
uint16_t rx_ring_tail = 0;

uint8_t current_slot = 0;
uint8_t fpga_is_ready = 0;

FATFS FatFs;
uint8_t slot_clk_configs[NUM_BITSTREAMS] = {0};
char slot_names[NUM_BITSTREAMS][MAX_NAME_LEN] = {0};
volatile uint8_t sd_is_mounted = 0;
__attribute__((section(".noinit"))) uint8_t last_active_slot;

// --- Telemetry Variables ---
volatile uint8_t telem_is_muted = 0;
volatile uint32_t telem_rate_ms = 1000;
volatile FastTarget_t fast_ch1 = TARGET_NONE;
volatile FastTarget_t fast_ch2 = TARGET_NONE;
volatile uint8_t pending_bq_adc_bits = 0;
/* USER CODE END Variables */

/* USER CODE BEGIN FunctionPrototypes */
void Init_App_RTOS(void);
void USB_Printf(const char *format, ...);
void StartUsbTask(void *argument);
void StartFpgaTask(void *argument);
void StartTelemetryTask(void *argument);
void StartJoystickTask(void *argument);
void StartLedTask(void *argument);
uint32_t Get_Safe_SPI_Prescaler(void);
/* USER CODE END FunctionPrototypes */

/* Hook prototypes */
void vApplicationStackOverflowHook(xTaskHandle xTask, signed char *pcTaskName);

/* USER CODE BEGIN 4 */

/**
 * Public setter called from frontend_api.c command parser
 */

// Define your I2C pins here (Update to match your STM32CubeIDE pinout)
#define I2C1_SCL_PORT GPIOB
#define I2C1_SCL_PIN  GPIO_PIN_6
#define I2C1_SDA_PORT GPIOB
#define I2C1_SDA_PIN  GPIO_PIN_7

// 1. Add this simple microsecond delay helper right above the recovery function
static void I2C_Delay_5us(void) {
    // A simple loop to waste CPU cycles (~5us at 64MHz).
    // This is safe to run inside an Interrupt context!
    for (volatile uint32_t i = 0; i < 100; i++) {
        __NOP();
    }
}

// 2. Update your I2C_Bus_Recovery function
void I2C_Bus_Recovery(I2C_HandleTypeDef *hi2c) {
    GPIO_InitTypeDef GPIO_InitStruct = {0};

    // 1. Disable the I2C peripheral to take manual control of the pins
    __HAL_I2C_DISABLE(hi2c);
    HAL_I2C_DeInit(hi2c);

    // 2. Configure SCL and SDA as standard Open-Drain GPIOs
    GPIO_InitStruct.Pin = I2C1_SCL_PIN;
    GPIO_InitStruct.Mode = GPIO_MODE_OUTPUT_OD;
    GPIO_InitStruct.Pull = GPIO_NOPULL;
    GPIO_InitStruct.Speed = GPIO_SPEED_FREQ_HIGH;
    HAL_GPIO_Init(I2C1_SCL_PORT, &GPIO_InitStruct);

    GPIO_InitStruct.Pin = I2C1_SDA_PIN;
    HAL_GPIO_Init(I2C1_SDA_PORT, &GPIO_InitStruct);

    // 3. Release SDA (Set High)
    HAL_GPIO_WritePin(I2C1_SDA_PORT, I2C1_SDA_PIN, GPIO_PIN_SET);

    // 4. Send 9 clock pulses on SCL to force the BQ25798 to release SDA
    for (int i = 0; i < 9; i++) {
        HAL_GPIO_WritePin(I2C1_SCL_PORT, I2C1_SCL_PIN, GPIO_PIN_RESET);
        I2C_Delay_5us(); // Replaced HAL_Delay
        HAL_GPIO_WritePin(I2C1_SCL_PORT, I2C1_SCL_PIN, GPIO_PIN_SET);
        I2C_Delay_5us(); // Replaced HAL_Delay
    }

    // 5. Generate a manual STOP condition (SCL High, then SDA Low to High)
    HAL_GPIO_WritePin(I2C1_SCL_PORT, I2C1_SCL_PIN, GPIO_PIN_RESET);
    I2C_Delay_5us();
    HAL_GPIO_WritePin(I2C1_SDA_PORT, I2C1_SDA_PIN, GPIO_PIN_RESET);
    I2C_Delay_5us();
    HAL_GPIO_WritePin(I2C1_SCL_PORT, I2C1_SCL_PIN, GPIO_PIN_SET);
    I2C_Delay_5us();
    HAL_GPIO_WritePin(I2C1_SDA_PORT, I2C1_SDA_PIN, GPIO_PIN_SET);
    I2C_Delay_5us();

    // 6. Re-initialize the I2C peripheral
    HAL_I2C_Init(hi2c);
}

void SPI3_SetBaudRate(uint32_t prescaler) {
    extern SPI_HandleTypeDef hspi3;
    __HAL_SPI_DISABLE(&hspi3);
    MODIFY_REG(hspi3.Instance->CR1, SPI_BAUDRATEPRESCALER_256, prescaler);
    __HAL_SPI_ENABLE(&hspi3);
}

uint32_t Get_Safe_SPI_Prescaler(void) {
    uint8_t divider = slot_clk_configs[current_slot];
    if (divider < 2) divider = 2;

    uint32_t target_pre = divider * 8; // Ensure SPI is at least 4x slower

    if (target_pre <= 2)   return SPI_BAUDRATEPRESCALER_2;
    if (target_pre <= 4)   return SPI_BAUDRATEPRESCALER_4;
    if (target_pre <= 8)   return SPI_BAUDRATEPRESCALER_8;
    if (target_pre <= 16)  return SPI_BAUDRATEPRESCALER_16;
    if (target_pre <= 32)  return SPI_BAUDRATEPRESCALER_32;
    if (target_pre <= 64)  return SPI_BAUDRATEPRESCALER_64;
    if (target_pre <= 128) return SPI_BAUDRATEPRESCALER_128;

    return SPI_BAUDRATEPRESCALER_256;
}

void Telemetry_SetFastTarget(uint8_t ch, const char* target) {
    FastTarget_t t = TARGET_NONE;
    if (strcmp(target, "1v2_core") == 0) t = TARGET_INA_1V2;
    else if (strcmp(target, "3v3_ext") == 0) t = TARGET_INA_3V3EXT;
    else if (strcmp(target, "3v3_fpga") == 0) t = TARGET_INA_3V3FPGA;
    else if (strcmp(target, "3v3_mcu") == 0) t = TARGET_INA_3V3MCU;
    else if (strcmp(target, "vbus") == 0) t = TARGET_BQ_VBUS;
    else if (strcmp(target, "vbat") == 0) t = TARGET_BQ_VBAT;

    if (ch == 1) fast_ch1 = t;
    else if (ch == 2) fast_ch2 = t;

    if (fast_ch1 == TARGET_BQ_VBUS || fast_ch1 == TARGET_BQ_VBAT ||
        fast_ch2 == TARGET_BQ_VBUS || fast_ch2 == TARGET_BQ_VBAT) {
        pending_bq_adc_bits = 13; // 6ms
    } else {
        pending_bq_adc_bits = 15; // 24ms
    }

    PowerMonitor_SetFastMode(&ina_1v2_core,  (fast_ch1 == TARGET_INA_1V2 || fast_ch2 == TARGET_INA_1V2));
    PowerMonitor_SetFastMode(&ina_3v3_ext,   (fast_ch1 == TARGET_INA_3V3EXT || fast_ch2 == TARGET_INA_3V3EXT));
    PowerMonitor_SetFastMode(&ina_3v3_fpga,  (fast_ch1 == TARGET_INA_3V3FPGA || fast_ch2 == TARGET_INA_3V3FPGA));
    PowerMonitor_SetFastMode(&ina_3v3_stm32, (fast_ch1 == TARGET_INA_3V3MCU || fast_ch2 == TARGET_INA_3V3MCU));
}

/* USER CODE END 4 */

/* USER CODE BEGIN Application */

void Init_App_RTOS(void) {
    const osMessageQueueAttr_t UsbQueue_attributes = { .name = "UsbQueue" };
    UsbQueueHandle = osMessageQueueNew(64, sizeof(UsbMsg_t), &UsbQueue_attributes);

    const osThreadAttr_t usbTask_attr = { .name = "UsbTask", .priority = (osPriority_t) osPriorityHigh, .stack_size = 1024 * 8 };
    UsbTaskHandle = osThreadNew(StartUsbTask, NULL, &usbTask_attr);

    const osThreadAttr_t fpgaTask_attr = { .name = "FpgaTask", .priority = (osPriority_t) osPriorityAboveNormal, .stack_size = 1024 * 4 };
    FpgaTaskHandle = osThreadNew(StartFpgaTask, NULL, &fpgaTask_attr);

    const osThreadAttr_t telemTask_attr = { .name = "TelemTask", .priority = (osPriority_t) osPriorityNormal, .stack_size = 1024 * 4 };
    TelemetryTaskHandle = osThreadNew(StartTelemetryTask, NULL, &telemTask_attr);

    const osThreadAttr_t joyTask_attr = { .name = "JoyTask", .priority = (osPriority_t) osPriorityLow, .stack_size = 512 * 4 };
    JoystickTaskHandle = osThreadNew(StartJoystickTask, NULL, &joyTask_attr);

    const osThreadAttr_t ledTask_attr = { .name = "LedTask", .priority = (osPriority_t) osPriorityLow, .stack_size = 128 * 4 };
    LedTaskHandle = osThreadNew(StartLedTask, NULL, &ledTask_attr);

    const osMessageQueueAttr_t FpgaTxQueue_attr = { .name = "FpgaTxQueue" };
    FpgaTxQueueHandle = osMessageQueueNew(8, sizeof(FpgaSpiPacket_t), &FpgaTxQueue_attr);

    const osSemaphoreAttr_t rx_sem_attr = { .name = "UsbRxSem" };
    UsbRxSemaphore = osSemaphoreNew(1, 0, &rx_sem_attr);

    const osSemaphoreAttr_t tx_sem_attr = { .name = "UsbTxSem" };
    // Create binary semaphore, initial count 1 (ready to TX)
    UsbTxSemaphore = osSemaphoreNew(1, 1, &tx_sem_attr);

    // Create binary semaphore, initial count 0 (empty)
    const osSemaphoreAttr_t i2c_sem_attr = { .name = "I2cDmaSem" };
    I2c1DmaSemaphore = osSemaphoreNew(1, 0, &i2c_sem_attr);

    const osMutexAttr_t i2c_mutex_attr = { .name = "I2cMutex" };
    I2c1Mutex = osMutexNew(&i2c_mutex_attr);

}

void USB_Printf(const char *format, ...) {
    if(hUsbDeviceFS.dev_state != USBD_STATE_CONFIGURED) return;
    UsbMsg_t msg;
    va_list args;
    va_start(args, format);
    vsnprintf(msg.data, sizeof(msg.data), format, args);
    va_end(args);
    if (UsbQueueHandle != NULL) osMessageQueuePut(UsbQueueHandle, &msg, 0, 0);
}

void Save_Configs(void) {
    if (!sd_is_mounted) return;
    FIL f; UINT bw;
    if (f_open(&f, "0:/sys.cfg", FA_WRITE | FA_CREATE_ALWAYS) == FR_OK) {
        f_write(&f, slot_clk_configs, NUM_BITSTREAMS, &bw);
        f_write(&f, slot_names, NUM_BITSTREAMS * MAX_NAME_LEN, &bw);
        f_close(&f);
    }
}

void Load_Configs(void) {
    if (!sd_is_mounted) return;
    FIL f; UINT br;
    if (f_open(&f, "0:/sys.cfg", FA_READ) == FR_OK) {
        f_read(&f, slot_clk_configs, NUM_BITSTREAMS, &br);
        f_read(&f, slot_names, NUM_BITSTREAMS * MAX_NAME_LEN, &br);
        f_close(&f);
    }
}

void Apply_Slot_Clock(uint8_t slot) {
    uint8_t divider = slot_clk_configs[slot];
    if (divider < 2)   divider = 2;
    if (divider > 128) divider = 128;

    uint32_t mco_div; float freq_val;
    if (divider <= 1)      { mco_div = RCC_MCODIV_1;   freq_val = 64.0f; }
    else if (divider <= 2) { mco_div = RCC_MCODIV_2;   freq_val = 32.0f; }
    else if (divider <= 4) { mco_div = RCC_MCODIV_4;   freq_val = 16.0f; }
    else if (divider <= 8) { mco_div = RCC_MCODIV_8;   freq_val = 8.0f;  }
    else if (divider <= 16){ mco_div = RCC_MCODIV_16;  freq_val = 4.0f;  }
    else if (divider <= 32){ mco_div = RCC_MCODIV_32;  freq_val = 2.0f;  }
    else if (divider <= 64){ mco_div = RCC_MCODIV_64;  freq_val = 1.0f;  }
    else                   { mco_div = RCC_MCODIV_128; freq_val = 0.5f;  }

    HAL_RCC_MCOConfig(RCC_MCO1, RCC_MCO1SOURCE_SYSCLK, mco_div);

    const char* displayName = slot_names[slot];
    if (slot == 0 && (displayName[0] == '\0' || strcmp(displayName, "unconfigured") == 0)) {
        displayName = "System Zero";
    }
    USB_Printf("LIVE_CLK:%d:%.2f MHz:%s\n", slot, freq_val, displayName);
}

// ============================================================================
// MAIN TASKS
// ============================================================================

void StartUsbTask(void *argument) {
    while (hUsbDeviceFS.dev_state != USBD_STATE_CONFIGURED) osDelay(100);
    osDelay(500);

    __HAL_RCC_PWR_CLK_ENABLE();
    __HAL_RCC_RTCAPB_CLK_ENABLE();
    HAL_PWR_EnableBkUpAccess();
    if (TAMP->BKP0R == 0x4F544150) {
		TAMP->BKP0R = 0x00000000;

		// Add this delay to allow USB descriptors to finish enumerating
		osDelay(2500);

		USB_Printf("OTA_LOG: === SYSTEM BOOTING (V2.1 OTA SUCCESS!) ===\n");
		USB_Printf("LOG: Rollback flag cleared. New firmware verified.\n");
	} else {
		USB_Printf("\n=== SYSTEM BOOTING ===\n");
	}

    Frontend_Init();
    static UsbMsg_t tx_msg;

    for(;;) {
        USBD_CDC_HandleTypeDef *hcdc = (USBD_CDC_HandleTypeDef*)hUsbDeviceFS.pClassData;
        bool processed_rx = false;

        uint16_t current_head = rx_ring_head;
        if (rx_ring_tail != current_head) {
            uint16_t contiguous_len = (current_head > rx_ring_tail) ?
                                      (current_head - rx_ring_tail) : (RX_RING_SIZE - rx_ring_tail);

            Frontend_ProcessBlock((uint8_t*)&rx_ring_buf[rx_ring_tail], contiguous_len);
            rx_ring_tail = (rx_ring_tail + contiguous_len) % RX_RING_SIZE;
            processed_rx = true;
        }

        Frontend_CheckTimeout();

        if (hcdc != NULL) {
			// 1. Check if messages exist BEFORE taking the semaphore
			if (osMessageQueueGetCount(UsbQueueHandle) > 0) {

				// 2. Sleep until the USB hardware is idle
				if (osSemaphoreAcquire(UsbTxSemaphore, 100) == osOK) {

					// 3. NOW pull the message. It is safe to overwrite tx_msg.
					if (osMessageQueueGet(UsbQueueHandle, &tx_msg, NULL, 0) == osOK) {
						if (hUsbDeviceFS.dev_state == USBD_STATE_CONFIGURED) {
							uint16_t len = strlen(tx_msg.data);
							if (len > USB_MSG_MAX_LEN - 1) len = USB_MSG_MAX_LEN - 1;

							// 4. Robust TX loop: Do NOT overwrite tx_msg until accepted
							uint8_t status;
							uint16_t timeout = 500; // 500ms safety net
							do {
								status = CDC_Transmit_FS((uint8_t*)tx_msg.data, len);
								if (status == USBD_BUSY) osDelay(1); // Yield to other tasks
								timeout--;
							} while (status == USBD_BUSY && timeout > 0);

							// If it failed or timed out, release the semaphore to prevent deadlocks.
							// If it succeeded (USBD_OK), the ISR will release it later.
							if (status != USBD_OK) {
								osSemaphoreRelease(UsbTxSemaphore);
							}
						} else {
							osSemaphoreRelease(UsbTxSemaphore); // USB dropped
						}
					} else {
						osSemaphoreRelease(UsbTxSemaphore); // Queue empty
					}
				}
			} else if (!processed_rx) {
				// No TX pending and no RX processed, sleep safely
				osSemaphoreAcquire(UsbRxSemaphore, 10);
			}
		}
    }
}

void StartFpgaTask(void *argument) {
    extern SPI_HandleTypeDef hspi3;
    uint8_t has_auto_programmed = 0;
    FpgaSpiPacket_t tx_packet;

    for(;;) {
    	// --- Auto-Boot Logic ---
		if (!has_auto_programmed && hUsbDeviceFS.dev_state == USBD_STATE_CONFIGURED) {
			osDelay(500);

			uint8_t target_slot = (last_active_slot < 16) ? last_active_slot : 0;

			// ALWAYS wait for the SD Card, even for slot 0
			uint8_t sd_wait = 30;
			while (!sd_is_mounted && sd_wait > 0) { osDelay(100); sd_wait--; }

			USB_Printf("LOG: Auto-programming Slot %d...\n", target_slot);
			SPI3_SetBaudRate(SPI_BAUDRATEPRESCALER_4); // MUST BE FAST FOR PROGRAMMING

            if (FPGA_Program_Slot(target_slot) == HAL_OK) {
                fpga_is_ready = 1; current_slot = target_slot; last_active_slot = target_slot;
                Apply_Slot_Clock(target_slot);
            } else if (target_slot != 0) {
                if (FPGA_Program_Slot(0) == HAL_OK) {
                    fpga_is_ready = 1; current_slot = 0; last_active_slot = 0;
                    Apply_Slot_Clock(0);
                }
            }
            has_auto_programmed = 1;
        }

        // --- Standard UI Programming Flag ---
        if (osThreadFlagsGet() & 0x01) {
            osThreadFlagsClear(0x01);
            SPI3_SetBaudRate(SPI_BAUDRATEPRESCALER_4); // MUST BE FAST FOR PROGRAMMING

            USB_Printf("Programming Slot %d...\n", current_slot);
            if (FPGA_Program_Slot(current_slot) == HAL_OK) {
                fpga_is_ready = 1; last_active_slot = current_slot;
                Apply_Slot_Clock(current_slot);
            } else {
                fpga_is_ready = 0; HAL_TIM_PWM_Stop(&htim1, TIM_CHANNEL_1);
                USB_Printf("LIVE_CLK:%d:FAILED\n", current_slot);
            }
        }

        // --- SPI Diagnostic Commands ---
        if (osMessageQueueGet(FpgaTxQueueHandle, &tx_packet, NULL, 50) == osOK) {
            if (!fpga_is_ready) {
                USB_Printf("ERR: FPGA not ready.\n");
                continue;
            }

            while (osSemaphoreAcquire(FpgaDmaSemaphore, 0) == osOK);
            __HAL_SPI_CLEAR_OVRFLAG(&hspi3);

            // APPLY SAFE CLOCK RATIO BEFORE TALKING TO RUNNING FPGA
            SPI3_SetBaudRate(Get_Safe_SPI_Prescaler());

            // Handle background Benchmarks triggered from the USB task
            if (tx_packet.cmd == 0x99) { Diag_RunSPIBenchmark(); continue; }
            if (tx_packet.cmd == 0x9A) { Diag_RunSPIBulk(); continue; }

            HAL_GPIO_WritePin(FPGA_CS_GPIO_Port, FPGA_CS_Pin, GPIO_PIN_RESET);
            if (HAL_SPI_TransmitReceive_DMA(&hspi3, (uint8_t*)&tx_packet, (uint8_t*)&fpga_rx_packet, sizeof(FpgaSpiPacket_t)) == HAL_OK) {
                osSemaphoreAcquire(FpgaDmaSemaphore, 100);
            }
            HAL_GPIO_WritePin(FPGA_CS_GPIO_Port, FPGA_CS_Pin, GPIO_PIN_SET);

            if (fpga_rx_packet.sync == FPGA_SYNC_BYTE) {
				USB_Printf("{\"type\":\"spi\",\"cmd\":%d,\"len\":%d,\"p0\":%d,\"p1\":%d,\"p2\":%d,\"p3\":%d}\n",
						   tx_packet.cmd, fpga_rx_packet.length,
						   fpga_rx_packet.payload[0], fpga_rx_packet.payload[1],
						   fpga_rx_packet.payload[2], fpga_rx_packet.payload[3]);
			} else {
				USB_Printf("ERR: SPI_RX Sync Loss\n");
			}
        }
    }
}

static void Format_PowerMonitor_Json(const char* id, PowerMonitor_Data_t *data, char *buffer, size_t max_len) {
    snprintf(buffer, max_len, "{\"type\":\"ina\",\"id\":\"%s\",\"v\":%.2f,\"i\":%.2f,\"p\":%.4f}",
        id, data->bus_voltage_V, data->current_mA, data->power_mW);
}

void StartTelemetryTask(void *argument) {
    char json_buf[256]; char fast_json[128];
    BQ25798_Data_t bq_data; PowerMonitor_Data_t ina_data;

    BQ25798_Init(&hi2c1);
    PowerMonitor_Init(&ina_1v2_core, &hi2c1, POWER_MONITOR_ADDR_40, 1.5f, 0.210f);
    PowerMonitor_Init(&ina_3v3_ext,  &hi2c1, POWER_MONITOR_ADDR_43, 1.0f, 0.320f);
    PowerMonitor_Init(&ina_3v3_fpga, &hi2c1, POWER_MONITOR_ADDR_4C, 1.0f, 0.320f);
    PowerMonitor_SetOffset(&ina_3v3_fpga, 0.47f);
    PowerMonitor_Init(&ina_3v3_stm32,&hi2c1, POWER_MONITOR_ADDR_4F, 1.0f, 0.320f);

    BQ25798_SetBatteryProfile(&BATT_PROFILE_LIION_3200);
    BQ25798_EnableBackup5V5();
    BQ25798_SetOTGCurrent(1000);

    BatterySOC_Init();

    static uint8_t last_sd_state = 0xFF;
    uint32_t tick = 0xFFFFFFFF;
    static float c1_v = 0, c1_i = 0, c2_v = 0, c2_i = 0;

    for(;;) {
        tick++;
        if (pending_bq_adc_bits != 0) { BQ25798_SetADCResolution(pending_bq_adc_bits); pending_bq_adc_bits = 0; }

        bool send_fast = false; bool bq_already_read_this_tick = false;

        if (!SysPower_IsSleeping()) {
            if (tick % 4 == 0) {
                bool need_bq = (fast_ch1 == TARGET_BQ_VBUS || fast_ch1 == TARGET_BQ_VBAT ||
                                fast_ch2 == TARGET_BQ_VBUS || fast_ch2 == TARGET_BQ_VBAT);
                if (need_bq && BQ25798_ReadAll(&bq_data) == HAL_OK) {
                    bq_already_read_this_tick = true;
                    if (fast_ch1 == TARGET_BQ_VBUS) { c1_v = bq_data.vbus_V; c1_i = bq_data.ibus_mA; }
                    else if (fast_ch1 == TARGET_BQ_VBAT) { c1_v = bq_data.vbat_V; c1_i = bq_data.ibat_mA; }
                    if (fast_ch2 == TARGET_BQ_VBUS) { c2_v = bq_data.vbus_V; c2_i = bq_data.ibus_mA; }
                    else if (fast_ch2 == TARGET_BQ_VBAT) { c2_v = bq_data.vbat_V; c2_i = bq_data.ibat_mA; }
                    send_fast = true;
                }
            }

            #define READ_INA_FAST(enum, ptr) \
                if (fast_ch1 == enum || fast_ch2 == enum) { \
                    if (PowerMonitor_Read(ptr, &ina_data) == HAL_OK) { \
                        if (fast_ch1 == enum) { c1_v = ina_data.bus_voltage_V; c1_i = ina_data.current_mA; } \
                        if (fast_ch2 == enum) { c2_v = ina_data.bus_voltage_V; c2_i = ina_data.current_mA; } \
                        send_fast = true; \
                    } \
                }

            READ_INA_FAST(TARGET_INA_1V2, &ina_1v2_core); READ_INA_FAST(TARGET_INA_3V3EXT, &ina_3v3_ext);
            READ_INA_FAST(TARGET_INA_3V3FPGA, &ina_3v3_fpga); READ_INA_FAST(TARGET_INA_3V3MCU, &ina_3v3_stm32);

            if (send_fast && hUsbDeviceFS.dev_state == USBD_STATE_CONFIGURED) {
                snprintf(fast_json, sizeof(fast_json), "{\"t\":\"f\",\"1\":[%.2f,%.2f],\"2\":[%.2f,%.2f]}\n", c1_v, c1_i, c2_v, c2_i);
                CDC_Transmit_FS((uint8_t*)fast_json, strlen(fast_json));
            }
        }

        uint32_t slow_ticks = SysPower_IsSleeping() ? 25 : ((telem_rate_ms < 5) ? 1 : (telem_rate_ms / 5));

        if (tick % slow_ticks == 0) {
            PowerMonitor_t* sensors[] = {&ina_1v2_core, &ina_3v3_ext, &ina_3v3_fpga, &ina_3v3_stm32};
            const char* sensor_ids[] = {"1v2_core", "3v3_ext", "3v3_fpga", "3v3_mcu"};

            if (SysPower_IsSleeping()) {
                for (int i = 0; i < 4; i++) PowerMonitor_TriggerSingleShot(sensors[i]);
                osDelay(1);
            }

            if (!bq_already_read_this_tick) BQ25798_ReadAll(&bq_data);

            float current_soc, calculated_r_int;
                        BatterySOC_Update(bq_data.vbat_V, bq_data.ibat_mA, &current_soc, &calculated_r_int);

			// --- BATTERY PROTECTION: Smart SOC Hysteresis ---
			static bool charge_paused_by_soc = false;
			if (!charge_paused_by_soc && current_soc >= 95.0f) {
				charge_paused_by_soc = true;
				BQ25798_SetChargeEnable(0);
				if (!telem_is_muted) USB_Printf("LOG: SOC reached 95%%. Charging paused to preserve battery.\n");
			} else if (charge_paused_by_soc && current_soc <= 90.0f) {
				charge_paused_by_soc = false;
				BQ25798_SetChargeEnable(1);
				if (!telem_is_muted) USB_Printf("LOG: SOC dropped to 90%%. Charging resumed.\n");
			}

			BQ25798_GetJson(&bq_data, json_buf, sizeof(json_buf));
            char* closing_brace = strrchr(json_buf, '}');
            if (closing_brace) {
                snprintf(closing_brace, sizeof(json_buf) - (closing_brace - json_buf),
                         ",\"soc\":%.1f,\"r_int\":%.3f}", current_soc, calculated_r_int);
            }

            if (!telem_is_muted) USB_Printf("%s\n", json_buf);

            // BQ Backup Reset Logic
            uint8_t vbus_stat = (bq_data.stat1 >> 1) & 0x0F;
            if ((vbus_stat == 0x0C) && (bq_data.stat0 & (1 << 1))) BQ25798_RearmBackup(3000);
            if (vbus_stat >= 0x01 && vbus_stat <= 0x06) {
                BQ25798_SetInputVoltageLimit(4600); // Keep pushing 4.6V
            }

            for (int i = 0; i < 4; i++) {
                if (PowerMonitor_Read(sensors[i], &ina_data) == HAL_OK) {
                    if (!SysPower_IsSleeping()) PowerMonitor_AutoScale(sensors[i], &ina_data);
                    Format_PowerMonitor_Json(sensor_ids[i], &ina_data, json_buf, sizeof(json_buf));
                    if (!telem_is_muted) USB_Printf("%s\n", json_buf);
                }
            }

            uint8_t current_sd_state = (HAL_GPIO_ReadPin(GPIOA, SD_DET_Pin) == GPIO_PIN_RESET) ? 1 : 0;
            if (current_sd_state != last_sd_state) {
                if (current_sd_state == 1) {
                    if (f_mount(&FatFs, "0:", 1) == FR_OK) {
                        sd_is_mounted = 1; Load_Configs(); USB_Printf("SYS: SD Card Mounted\r\n");
                    } else {
                        Error_Raise(ERR_SD_MOUNT_FAIL, SEV_WARNING, "f_mount returned error");
                    }
                } else if (last_sd_state != 0xFF) {
                    sd_is_mounted = 0; f_mount(NULL, "0:", 0); USB_Printf("SYS: SD Card Removed\r\n");
                }
                last_sd_state = current_sd_state;
            }
            USB_Printf("{\"type\":\"sys\",\"sd\":%d}\n", current_sd_state);

            // ---> ADD THIS NEW BLOCK <---
            char gpio_json[128];
            Pinmux_GetInputTelemetryJson(gpio_json, sizeof(gpio_json));
            if (gpio_json[0] != '\0' && !telem_is_muted) {
                USB_Printf("%s\n", gpio_json);
            }
        }
        osDelay(5);
    }
}

// ============================================================================
// PERIPHERAL TASKS
// ============================================================================

void StartJoystickTask(void *argument) {
    Joystick_Init();
    for(;;) {
        JoyAction_t action = Joystick_Process();

        if (action != JOY_NONE) {
            JoystickMap_t map = Joystick_GetMap();

            if (action == JOY_UP || action == JOY_DOWN) {
                if (map.ud == 0) {
                    uint32_t val = slot_clk_configs[current_slot];
                    if (action == JOY_UP && val > 2) val /= 2;
                    else if (action == JOY_DOWN && val < 128) val *= 2;
                    slot_clk_configs[current_slot] = val; Save_Configs(); Apply_Slot_Clock(current_slot);
                } else if (map.ud == 1) {
                    BQ25798_TogglePFM(); USB_Printf("LOG: BQ PFM Modes Toggled\n");
                }
            }
            else if (action == JOY_LEFT || action == JOY_RIGHT) {
                if (map.lr == 0) {
                    if (action == JOY_LEFT) current_slot = (current_slot == 0) ? NUM_BITSTREAMS - 1 : current_slot - 1;
                    else current_slot = (current_slot + 1) % NUM_BITSTREAMS;
                    USB_Printf("Slot: %d\n", current_slot);
                } else if (map.lr == 1) {
                    BQ25798_AdjustVOTG(action == JOY_RIGHT ? 100 : -100);
                    USB_Printf("LOG: BQ VOTG Adjusted\n");
                }
            }
            else if (action == JOY_CENTER) {
                if (map.cen == 0) osThreadFlagsSet(FpgaTaskHandle, 0x01);
                else if (map.cen == 1) { BQ25798_ToggleAutoRearm(); USB_Printf("LOG: BQ Auto-Rearm Toggled\n"); }
            }
        }
        osDelay(50);
    }
}

void StartLedTask(void *argument) {
    LED_Init();
    for(;;) {
        LED_ToggleHeartbeat();
        LED_SetFpgaReady(fpga_is_ready);
        osDelay(500);
    }
}

// Triggered when an I2C DMA Memory Write finishes
void HAL_I2C_MemTxCpltCallback(I2C_HandleTypeDef *hi2c) {
    extern osSemaphoreId_t I2c1DmaSemaphore;
    if (hi2c->Instance == I2C1 && I2c1DmaSemaphore != NULL) {
        osSemaphoreRelease(I2c1DmaSemaphore);
    }
}

// Triggered when an I2C DMA Memory Read finishes
void HAL_I2C_MemRxCpltCallback(I2C_HandleTypeDef *hi2c) {
    extern osSemaphoreId_t I2c1DmaSemaphore;
    if (hi2c->Instance == I2C1 && I2c1DmaSemaphore != NULL) {
        osSemaphoreRelease(I2c1DmaSemaphore);
    }
}

// Triggered if the device NACKs or the bus hangs
// Triggered if the device NACKs or the bus hangs
void HAL_I2C_ErrorCallback(I2C_HandleTypeDef *hi2c) {
    extern osSemaphoreId_t I2c1DmaSemaphore;
    if (hi2c->Instance == I2C1) {

        // 1. Recover the hung bus
        I2C_Bus_Recovery(hi2c);

        // 2. Release semaphore so the telemetry task doesn't freeze forever
        if (I2c1DmaSemaphore != NULL) {
            osSemaphoreRelease(I2c1DmaSemaphore);
        }
    }
}

/* USER CODE END Application */
